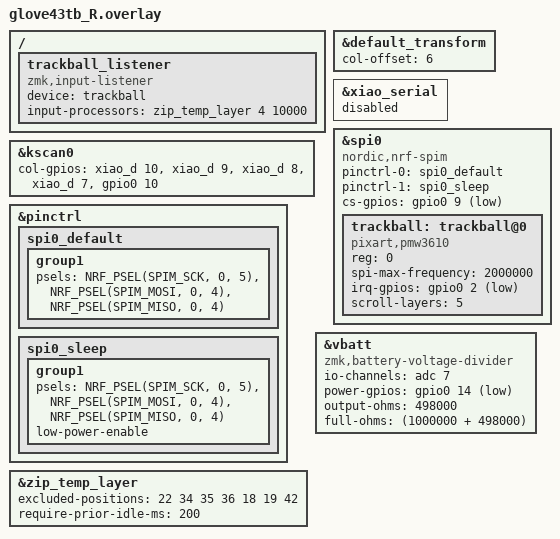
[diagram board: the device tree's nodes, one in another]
#include "glove43tb.dtsi"
#include <input/processors.dtsi>

&default_transform {
    col-offset = <6>;
};

&kscan0 {
        col-gpios
            = <&xiao_d 10 GPIO_ACTIVE_HIGH>
            , <&xiao_d 9 GPIO_ACTIVE_HIGH>
            , <&xiao_d 8 GPIO_ACTIVE_HIGH>
            , <&xiao_d 7 GPIO_ACTIVE_HIGH>
            , <&gpio0 10 GPIO_ACTIVE_HIGH>
            ;
};

/* --- 3. トラックボール使用時にレイヤーを一時的に有効化 --- */
/ {
    trackball_listener {
        status = "okay";
        compatible = "zmk,input-listener";
        device = <&trackball>;
        /* レイヤー4を10秒間有効化 */
        input-processors = <&zip_temp_layer 4 10000>;
    };
};

&pinctrl {
    spi0_default: spi0_default {
        group1 {
            psels = <NRF_PSEL(SPIM_SCK, 0, 5)>,
                <NRF_PSEL(SPIM_MOSI, 0, 4)>,
                <NRF_PSEL(SPIM_MISO, 0, 4)>;
        };
    };

    spi0_sleep: spi0_sleep {
        group1 {
            psels = <NRF_PSEL(SPIM_SCK, 0, 5)>,
                <NRF_PSEL(SPIM_MOSI, 0, 4)>,
                <NRF_PSEL(SPIM_MISO, 0, 4)>;
            low-power-enable;
        };
    };
};

&xiao_serial { status = "disabled"; };

&spi0 {
    status = "okay";
    compatible = "nordic,nrf-spim";
    pinctrl-0 = <&spi0_default>;
    pinctrl-1 = <&spi0_sleep>;
    pinctrl-names = "default", "sleep";
    cs-gpios = <&gpio0 9 GPIO_ACTIVE_LOW>;

    /* --- 2. トラックボールの Input Listener 設定 --- */
    trackball: trackball@0 {
        status = "okay";
        compatible = "pixart,pmw3610";
        reg = <0>;
        spi-max-frequency = <2000000>;
        irq-gpios = <&gpio0 2 (GPIO_ACTIVE_LOW | GPIO_PULL_UP)>;
    
        /* zmk-pmw3610-driverの旧AMLは無効化 */
        // automouse-layer = <4>;
        /* zmk-pmw3610-driverのスクロールレイヤーは残す */
        scroll-layers = <5>;

        // arrows {
        //     layers = <3>;
        //     bindings =
        //         <&kp RIGHT_ARROW>,
        //         <&kp LEFT_ARROW>,
        //         <&kp UP_ARROW>,
        //         <&kp DOWN_ARROW>;
        //     tick = <10>;
        //     wait-ms = <5>;
        //     tap-ms = <5>;
        // };
    };
};

/* --- 1. Input Processor 設定 --- */
&zip_temp_layer {
    /* 非マウスキー押下でAML解除しないキー（例：Z_SHIFT,CTRL,WIN,ALT,J,K,SHIFT） */
    excluded-positions = <22 34 35 36 18 19 42>;

    /* キー入力後200msはAML発動禁止（誤爆防止） */
    require-prior-idle-ms = <200>;
};

&vbatt {
    compatible = "zmk,battery-voltage-divider";
    io-channels = <&adc 7>;
    power-gpios = <&gpio0 14 (GPIO_OPEN_DRAIN | GPIO_ACTIVE_LOW)>;
    output-ohms = <498000>;
    full-ohms = <(1000000 + 498000)>;
};
